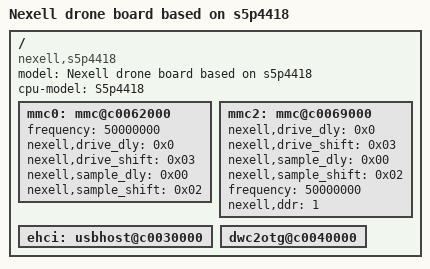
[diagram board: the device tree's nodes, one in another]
/*
 * (C) Copyright 2016 Nexell
 * Youngbok, Park <park@nexell.co.kr>
 *
 * SPDX-License-Identifier:      GPL-2.0+
 */

/dts-v1/;
#include "s5p4418.dtsi"

/ {
	model = "Nexell drone board based on s5p4418";
	cpu-model = "S5p4418";

	compatible = "nexell,s5p4418";

	mmc0:mmc@c0062000 {
		frequency = <50000000>;
		nexell,drive_dly = <0x0>;
		nexell,drive_shift = <0x03>;
		nexell,sample_dly = <0x00>;
		nexell,sample_shift = <0x02>;
		status = "okay";
	};

	mmc2:mmc@c0069000 {
		nexell,drive_dly = <0x0>;
		nexell,drive_shift = <0x03>;
		nexell,sample_dly = <0x00>;
		nexell,sample_shift = <0x02>;
		frequency = <50000000>;
		nexell,ddr = <1>;
		status ="okay";
	};

	ehci:usbhost@c0030000 {
		status = "okay";
	};

	dwc2otg@c0040000 {
		status = "okay";
	};
};
